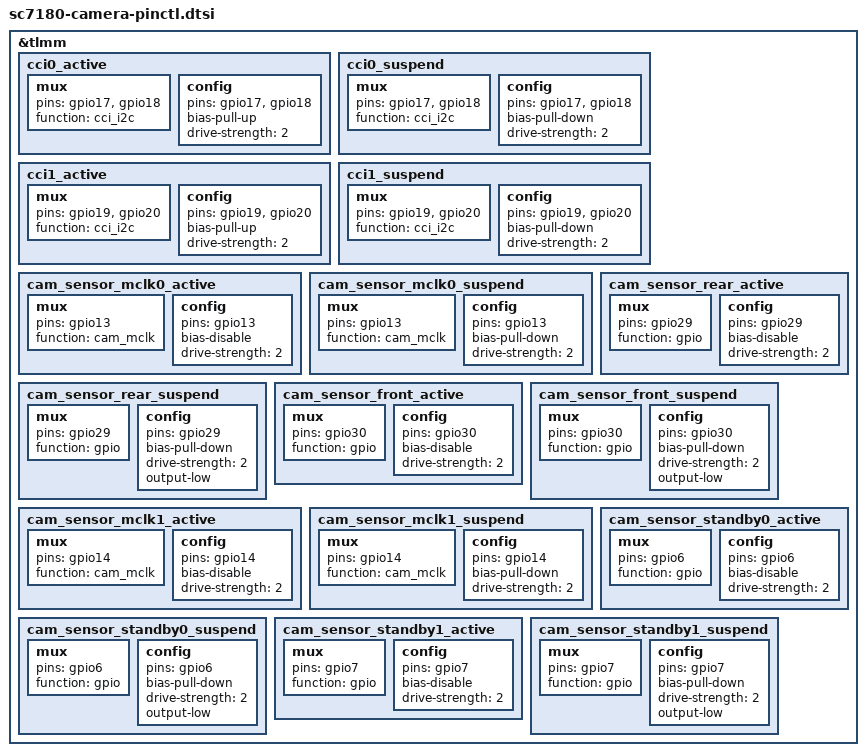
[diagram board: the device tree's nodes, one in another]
// SPDX-License-Identifier: BSD-3-Clause
/*
 * Copyright (c) 2019-2020, The Linux Foundation. All rights reserved.
 *
 * This program is free software; you can redistribute it and/or modify
 * it under the terms of the GNU General Public License version 2 and
 * only version 2 as published by the Free Software Foundation.
 *
 * This program is distributed in the hope that it will be useful,
 * but WITHOUT ANY WARRANTY; without even the implied warranty of
 * MERCHANTABILITY or FITNESS FOR A PARTICULAR PURPOSE.  See the
 * GNU General Public License for more details.
 */

&tlmm {
	cci0_active: cci0_active {
		mux {
			/* DATA, CLK */
			pins = "gpio17", "gpio18";
			function = "cci_i2c";
		};
		config {
			pins = "gpio17", "gpio18";
			bias-pull-up; /* PULL UP */
			drive-strength = <2>; /* 2 MA */
		};
	};

	cci0_suspend: cci0_suspend {
		mux {
			/* DATA, CLK */
			pins = "gpio17", "gpio18";
			function = "cci_i2c";
		};
		config {
			pins = "gpio17", "gpio18";
			bias-pull-down; /* PULL DOWN */
			drive-strength = <2>; /* 2 MA */
		};
	};

	cci1_active: cci1_active {
		mux {
			/* DATA, CLK */
			pins = "gpio19", "gpio20";
			function = "cci_i2c";
		};
		config {
			pins = "gpio19", "gpio20";
			bias-pull-up; /* PULL UP */
			drive-strength = <2>; /* 2 MA */
		};
	};

	cci1_suspend: cci1_suspend {
		mux {
			/* DATA, CLK */
			pins = "gpio19", "gpio20";
			function = "cci_i2c";
		};
		config {
			pins = "gpio19", "gpio20";
			bias-pull-down; /* PULL DOWN */
			drive-strength = <2>; /* 2 MA */
		};
	};

	cam_sensor_mclk0_active: cam_sensor_mclk0_active {
		/* MCLK0 */
		mux {
			pins = "gpio13";
			function = "cam_mclk";
		};
		config {
			pins = "gpio13";
			bias-disable; /* No PULL */
			drive-strength = <2>; /* 2 MA */
		};
	};

	cam_sensor_mclk0_suspend: cam_sensor_mclk0_suspend {
		/* MCLK0 */
		mux {
			pins = "gpio13";
			function = "cam_mclk";
		};
		config {
			pins = "gpio13";
			bias-pull-down; /* PULL DOWN */
			drive-strength = <2>; /* 2 MA */
		};
	};

	cam_sensor_rear_active: cam_sensor_rear_active {
		/* RESET */
		mux {
			pins = "gpio29";
			function = "gpio";
		};
		config {
			pins = "gpio29";
			bias-disable; /* No PULL */
			drive-strength = <2>; /* 2 MA */
		};
	};

	cam_sensor_rear_suspend: cam_sensor_rear_suspend {
		/* RESET */
		mux {
			pins = "gpio29";
			function = "gpio";
		};
		config {
			pins = "gpio29";
			bias-pull-down; /* PULL DOWN */
			drive-strength = <2>; /* 2 MA */
			output-low;
		};
	};

	cam_sensor_front_active: cam_sensor_front_active {
		/* RESET  */
		mux {
			pins = "gpio30";
			function = "gpio";
		};
		config {
			pins = "gpio30";
			bias-disable; /* No PULL */
			drive-strength = <2>; /* 2 MA */
		};
	};

	cam_sensor_front_suspend: cam_sensor_front_suspend {
		/* RESET */
		mux {
			pins = "gpio30";
			function = "gpio";
		};
		config {
			pins = "gpio30";
			bias-pull-down; /* PULL DOWN */
			drive-strength = <2>; /* 2 MA */
			output-low;
		};
	};

	cam_sensor_mclk1_active: cam_sensor_mclk1_active {
		/* MCLK1 */
		mux {
			pins = "gpio14";
			function = "cam_mclk";
		};
		config {
			pins = "gpio14";
			bias-disable; /* No PULL */
			drive-strength = <2>; /* 2 MA */
		};
	};

	cam_sensor_mclk1_suspend: cam_sensor_mclk1_suspend {
		/* MCLK1 */
		mux {
			pins = "gpio14";
			function = "cam_mclk";
		};
		config {
			pins = "gpio14";
			bias-pull-down; /* PULL DOWN */
			drive-strength = <2>; /* 2 MA */
		};
	};

	cam_sensor_standby0_active: cam_sensor_standby0_active {
		/* STANDBY0 */
		mux {
			pins = "gpio6";
			function = "gpio";
		};
		config {
			pins = "gpio6";
			bias-disable; /* No PULL */
			drive-strength = <2>; /* 2 MA */
		};
	};

	cam_sensor_standby0_suspend: cam_sensor_standby0_suspend {
		/* STANDBY0 */
		mux {
			pins = "gpio6";
			function = "gpio";
		};
		config {
			pins = "gpio6";
			bias-pull-down; /* PULL DOWN */
			drive-strength = <2>; /* 2 MA */
			output-low;
		};
	};

	cam_sensor_standby1_active: cam_sensor_standby1_active {
		/* STANDBY1 */
		mux {
			pins = "gpio7";
			function = "gpio";
		};
		config {
			pins = "gpio7";
			bias-disable; /* No PULL */
			drive-strength = <2>; /* 2 MA */
		};
	};

	cam_sensor_standby1_suspend: cam_sensor_standby1_suspend {
		/* STANDBY1 */
		mux {
			pins = "gpio7";
			function = "gpio";
		};
		config {
			pins = "gpio7";
			bias-pull-down; /* PULL DOWN */
			drive-strength = <2>; /* 2 MA */
			output-low;
		};
	};
};
